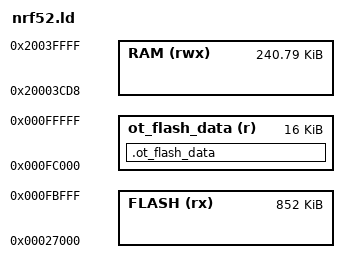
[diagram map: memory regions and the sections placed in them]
/* Linker script to configure memory regions. */

SEARCH_DIR(.)
GROUP(-lgcc -lc -lnosys)

MEMORY
{
  FLASH (rx) : ORIGIN = 0x27000, LENGTH = 0xd5000
  RAM (rwx) :  ORIGIN = 0x20003cd8, LENGTH = 0x3C328
  ot_flash_data (r) : ORIGIN = 0xfc000, LENGTH = 0x4000
}

SECTIONS
{
  . = ALIGN(4);
  .ot_flash_data :
  {
    PROVIDE(__start_ot_flash_data = ORIGIN(ot_flash_data));
    KEEP(*(SORT(.ot_flash_data*)))
    PROVIDE(__stop_ot_flash_data = ORIGIN(ot_flash_data) + LENGTH(ot_flash_data));
  } > ot_flash_data
}

SECTIONS
{
  . = ALIGN(4);
  .mem_section_dummy_ram :
  {
  }
  .fs_data :
  {
    PROVIDE(__start_fs_data = .);
    KEEP(*(.fs_data))
    PROVIDE(__stop_fs_data = .);
  } > RAM
  .log_filter_data :
  {
    PROVIDE(__start_log_filter_data = .);
    KEEP(*(SORT(.log_filter_data*)))
    PROVIDE(__stop_log_filter_data = .);
  } > RAM
  .log_dynamic_data :
  {
    PROVIDE(__start_log_dynamic_data = .);
    KEEP(*(SORT(.log_dynamic_data*)))
    PROVIDE(__stop_log_dynamic_data = .);
  } > RAM

} INSERT AFTER .data;

SECTIONS
{
  .mem_section_dummy_rom :
  {
  }
  .sdh_ble_observers :
  {
    PROVIDE(__start_sdh_ble_observers = .);
    KEEP(*(SORT(.sdh_ble_observers*)))
    PROVIDE(__stop_sdh_ble_observers = .);
  } > FLASH
  .log_const_data :
  {
    PROVIDE(__start_log_const_data = .);
    KEEP(*(SORT(.log_const_data*)))
    PROVIDE(__stop_log_const_data = .);
  } > FLASH
  .sdh_soc_observers :
  {
    PROVIDE(__start_sdh_soc_observers = .);
    KEEP(*(SORT(.sdh_soc_observers*)))
    PROVIDE(__stop_sdh_soc_observers = .);
  } > FLASH
  .sdh_stack_observers :
  {
    PROVIDE(__start_sdh_stack_observers = .);
    KEEP(*(SORT(.sdh_stack_observers*)))
    PROVIDE(__stop_sdh_stack_observers = .);
  } > FLASH
  .sdh_req_observers :
  {
    PROVIDE(__start_sdh_req_observers = .);
    KEEP(*(SORT(.sdh_req_observers*)))
    PROVIDE(__stop_sdh_req_observers = .);
  } > FLASH
  .sdh_state_observers :
  {
    PROVIDE(__start_sdh_state_observers = .);
    KEEP(*(SORT(.sdh_state_observers*)))
    PROVIDE(__stop_sdh_state_observers = .);
  } > FLASH
  .log_backends :
  {
    PROVIDE(__start_log_backends = .);
    KEEP(*(SORT(.log_backends*)))
    PROVIDE(__stop_log_backends = .);
  } > FLASH
    .nrf_balloc :
  {
    PROVIDE(__start_nrf_balloc = .);
    KEEP(*(.nrf_balloc))
    PROVIDE(__stop_nrf_balloc = .);
  } > FLASH

} INSERT AFTER .text

ASSERT(__start_ot_flash_data > __etext, "Section ot_flash_data overlaps text section")
INCLUDE "nrf_common.ld"
